# MCXA156 register map
Vendor: nxp.com; File version: 1.0
CPU: CM33 r2p0, little endian, no MPU, FPU, VTOR, 3 interrupt priority bits
Registers are 32-bit, read-write, reset 0x0 unless marked. A register's access mark holds for its fields unless they carry their own. Offsets are from the block's base; [hi:lo] are bit positions; {n}, {i} and the like mark numbered series.

## FLEXIO0 — FLEXIO
Base 0x40099000
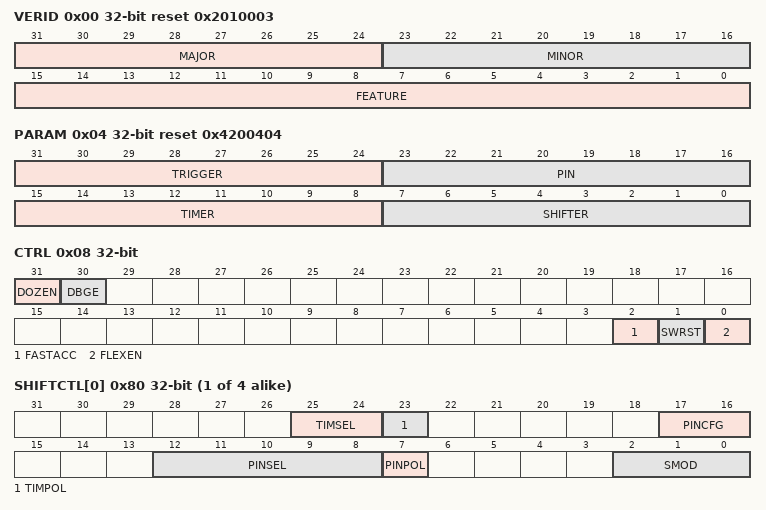
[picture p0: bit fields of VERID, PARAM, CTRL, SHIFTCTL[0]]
0x00 VERID ro reset 0x2010003 — Version ID
  [31:24] MAJOR — Major Version Number
  [23:16] MINOR — Minor Version Number
  [15:0] FEATURE — Feature Specification Number
    0=Standard features implemented; 1=state_logic_parallel (State, logic, and parallel modes supported); 2=pinctrl (Pin control registers supported); 3=state_logic_parallel_pinctrl (State, logic, and parallel modes, plus pin control registers supported)
0x04 PARAM ro reset 0x4200404 — Parameter
  [31:24] TRIGGER — Trigger Number
  [23:16] PIN — Pin Number
  [15:8] TIMER — Timer Number
  [7:0] SHIFTER — Shifter Number
0x08 CTRL — FLEXIO Control
  [31] DOZEN — Doze Enable
    0=enable; 1=disable
  [30] DBGE — Debug Enable
    0=disable; 1=emable (Enable)
  [2] FASTACC — Fast Access
    0=normal; 1=fast
  [1] SWRST — Software Reset
    0=Disabled; 1=Enabled
  [0] FLEXEN — FLEXIO Enable
    0=disable; 1=enable
0x0C PIN ro — Pin State
  [31:0] PDI — Pin Data Input
0x10 SHIFTSTAT write-1-clears — Shifter Status
  [3:0] SSF write-1-clears — Shifter Status Flag
    on read: 0=CLR (Clear); 1=SET
0x14 SHIFTERR write-1-clears — Shifter Error
  [3:0] SEF write-1-clears — Shifter Error Flag
    on read: 0=CLR (Clear); 1=SET
0x18 TIMSTAT write-1-clears — Timer Status Flag
  [3:0] TSF write-1-clears
    on read: 0=CLR (Clear); 1=SET
0x20 SHIFTSIEN — Shifter Status Interrupt Enable
  [3:0] SSIE
0x24 SHIFTEIEN — Shifter Error Interrupt Enable
  [3:0] SEIE
0x28 TIMIEN — Timer Interrupt Enable
  [3:0] TEIE — Timer Status Interrupt Enable
0x30 SHIFTSDEN — Shifter Status DMA Enable
  [3:0] SSDE
0x38 TIMERSDEN — Timer Status DMA Enable
  [3:0] TSDE
0x40 SHIFTSTATE — Shifter State
  [2:0] STATE — Current State Pointer
0x48 TRGSTAT write-1-clears — Trigger Status
  [3:0] ETSF write-1-clears — External Trigger Status Flag
    on read: 0=CLR (Clear); 1=SET
0x4C TRIGIEN — External Trigger Interrupt Enable
  [3:0] TRIE
0x50 PINSTAT write-1-clears — Pin Status
  [31:0] PSF write-1-clears — Pin Status Flag
    on read: 0=CLR (Clear); 1=SET
0x54 PINIEN — Pin Interrupt Enable
  [31:0] PSIE — Pin Status Interrupt Enable
0x58 PINREN — Pin Rising Edge Enable
  [31:0] PRE — Pin Rising Edge
0x5C PINFEN — Pin Falling Edge Enable
  [31:0] PFE — Pin Falling Edge
0x60 PINOUTD — Pin Output Data
  [31:0] OUTD — Output Data
0x64 PINOUTE — Pin Output Enable
  [31:0] OUTE — Output Enable
0x68 PINOUTDIS — Pin Output Disable
  [31:0] OUTDIS — Output Disable
0x6C PINOUTCLR — Pin Output Clear
  [31:0] OUTCLR — Output Clear
0x70 PINOUTSET — Pin Output Set
  [31:0] OUTSET — Output Set
0x74 PINOUTTOG — Pin Output Toggle
  [31:0] OUTTOG — Output Toggle
{0x80+4i} SHIFTCTL[{i}] (i=0..3) — Shifter Control
  [25:24] TIMSEL — Timer Select
  [23] TIMPOL — Timer Polarity
    0=posedge (Positive edge); 1=negedge (Negative edge)
  [17:16] PINCFG — Shifter Pin Configuration
    0=disable (Shifter pin output disabled); 1=opend_bidirouten (Shifter pin open-drain or bidirectional output enable); 2=bidir_outdata (Shifter pin bidirectional output data); 3=output (Shifter pin output)
  [12:8] PINSEL — Shifter Pin Select
  [7] PINPOL — Shifter Pin Polarity
    0=active_high; 1=active_low
  [2:0] SMOD — Shifter Mode
    0=disable; 1=Receive mode; capture the current shifter content into SHIFTBUF on expiration of the timer; 2=Transmit mode; load SHIFTBUF contents into the shifter on expiration of the timer; 4=Match Store mode; shifter data is compared to SHIFTBUF content on expiration of the timer; 5=Match Continuous mode; shifter data is continuously compared to SHIFTBUF contents; 6=State mode; SHIFTBUF contents store programmable state attributes; 7=Logic mode; SHIFTBUF contents implement programmable logic lookup table
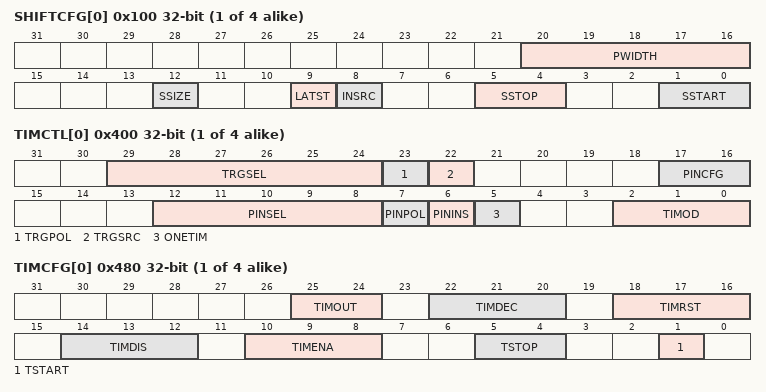
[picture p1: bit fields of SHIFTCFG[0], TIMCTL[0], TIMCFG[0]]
{0x100+4i} SHIFTCFG[{i}] (i=0..3) — Shifter Configuration
  [20:16] PWIDTH — Parallel Width
  [12] SSIZE — Shifter Size
    0=width32 (32-bit); 1=width24 (24-bit)
  [9] LATST — Late Store
    0=preshift (Store the pre-shift register state); 1=postshift (Store the post-shift register state)
  [8] INSRC — Input Source
    0=pin; 1=shifter_nplus1 (Shifter n+1 output)
  [5:4] SSTOP — Shifter Stop
    0=Stop bit disabled for Transmitter, Receiver, and Match Store modes; 1=Stop bit disabled for Transmitter, Receiver, and Match Store modes; when timer is in stop condition, Receiver and Match Store modes store receive data on the configured shift edge; 2=Transmitter mode outputs stop bit value 0 in Match Store mode; if stop bit is not 0, Receiver and Match Store modes set error flag (when timer is in stop condition, these modes also store receive data on the configured shift edge); 3=Transmitter mode outputs stop bit value 1 in Match Store mode; if stop bit is not 1, Receiver and Match Store modes set error flag (when timer is in stop condition, these modes also store receive data on the configured shift edge)
  [1:0] SSTART — Shifter Start
    0=Start bit disabled for Transmitter, Receiver, and Match Store modes; Transmitter mode loads data on enable; 1=Start bit disabled for Transmitter, Receiver, and Match Store modes; Transmitter mode loads data on first shift; 2=Transmitter mode outputs start bit value 0 before loading data on first shift; if start bit is not 0, Receiver and Match Store modes set error flag; 3=Transmitter mode outputs start bit value 1 before loading data on first shift; if start bit is not 1, Receiver and Match Store modes set error flag
{0x200+4i} SHIFTBUF[{i}] (i=0..3) — Shifter Buffer
  [31:0] SHIFTBUF — Shift Buffer
{0x280+4i} SHIFTBUFBIS[{i}] (i=0..3) — Shifter Buffer Bit Swapped
  [31:0] SHIFTBUFBIS — Shift Buffer
{0x300+4i} SHIFTBUFBYS[{i}] (i=0..3) — Shifter Buffer Byte Swapped
  [31:0] SHIFTBUFBYS — Shift Buffer
{0x380+4i} SHIFTBUFBBS[{i}] (i=0..3) — Shifter Buffer Bit Byte Swapped
  [31:0] SHIFTBUFBBS — Shift Buffer
{0x400+4i} TIMCTL[{i}] (i=0..3) — Timer Control
  [29:24] TRGSEL — Trigger Select
  [23] TRGPOL — Trigger Polarity
    0=active_high; 1=active_low
  [22] TRGSRC — Trigger Source
    0=ext_trig (External); 1=internal_trig
  [17:16] PINCFG — Timer Pin Configuration
    0=outdisable (Timer pin output disabled); 1=opend_bidirouten (Timer pin open-drain or bidirectional output enable); 2=bidir_outdata (Timer pin bidirectional output data); 3=output (Timer pin output)
  [12:8] PINSEL — Timer Pin Select
  [7] PINPOL — Timer Pin Polarity
    0=active_high; 1=active_low
  [6] PININS — Timer Pin Input Select
    0=PINSEL selects timer pin input and output; 1=pinselplus1 (PINSEL + 1 selects the timer pin input; timer pin output remains selected by PINSEL)
  [5] ONETIM — Timer One Time Operation
    0=not_blocked (Generate the timer enable event as normal); 1=blocked (Block the timer enable event unless the timer status flag is clear)
  [2:0] TIMOD — Timer Mode
    0=disable (Timer disabled); 1=dual8bit_baud (Dual 8-bit counters baud mode); 2=dual8bit_pwm_h (Dual 8-bit counters PWM high mode); 3=Single 16-bit counter mode; 4=single16bit_disable (Single 16-bit counter disable mode); 5=dual8bit_word (Dual 8-bit counters word mode); 6=dual8bit_pwm_l (Dual 8-bit counters PWM low mode); 7=single16bit_in_capture (Single 16-bit input capture mode)
{0x480+4i} TIMCFG[{i}] (i=0..3) — Timer Configuration
  [25:24] TIMOUT — Timer Output
    0=one (Logic one when enabled; not affected by timer reset); 1=zero (Logic zero when enabled; not affected by timer reset); 2=one_tmrreset (Logic one when enabled and on timer reset); 3=zero_tmrreset (Logic zero when enabled and on timer reset)
  [22:20] TIMDEC — Timer Decrement
    0=flexio_clk_shiftclk_tmr_out (Decrement counter on FLEXIO clock; shift clock equals timer output); 1=trig_edge_shiftclk_tmr_out (Decrement counter on trigger input (both edges); shift clock equals timer output); 2=pin_edge_shiftclk_tmr_out (Decrement counter on pin input (both edges); shift clock equals pin input); 3=trig_edge_shiftclk_trig_in (Decrement counter on trigger input (both edges); shift clock equals trigger input); 4=flexio_clk_div16_shiftclk_tmr_out (Decrement counter on FLEXIO clock divided by 16; shift clock equals timer output); 5=flexio_clk_div256_shiftclk_tmr_out (Decrement counter on FLEXIO clock divided by 256; shift clock equals timer output); 6=pin_rise_shiftclk_pin_in (Decrement counter on pin input (rising edge); shift clock equals pin input); 7=trig_rise_shiftclk_trig_in (Decrement counter on trigger input (rising edge); shift clock equals trigger input)
  [18:16] TIMRST — Timer Reset
    0=Never reset timer; 1=tmr_out_hi (Timer reset on timer output high.); 2=pin_eq_tmr_out (Timer reset on timer pin equal to timer output); 3=trig_eq_tmr_out (Timer reset on timer trigger equal to timer output); 4=pin_rise_edge (Timer reset on timer pin rising edge); 6=trig_rise_edge (Timer reset on trigger rising edge); 7=trig_edge (Timer reset on trigger rising or falling edge)
  [14:12] TIMDIS — Timer Disable
    0=never (Timer never disabled); 1=tmr_nminus1 (Timer disabled on timer n-1 disable); 2=tmr_cmp (Timer disabled on timer compare (upper 8 bits match and decrement)); 3=tmr_cmp_triglow (Timer disabled on timer compare (upper 8 bits match and decrement) and trigger low); 4=pin_edge (Timer disabled on pin rising or falling edge); 5=pin_edge_trighi (Timer disabled on pin rising or falling edge provided trigger is high); 6=trig_falledge (Timer disabled on trigger falling edge)
  [10:8] TIMENA — Timer Enable
    0=enable (Timer always enabled); 1=tmr_nminus1_en (Timer enabled on timer n-1 enable); 2=tmr_trighi_en (Timer enabled on trigger high); 3=tmr_trig_pin_hi_en (Timer enabled on trigger high and pin high); 4=tmr_pinrise_en (Timer enabled on pin rising edge); 5=tmr_pinrise_trighi_en (Timer enabled on pin rising edge and trigger high); 6=tmr_trigrise_en (Timer enabled on trigger rising edge); 7=tmr_trigedge_en (Timer enabled on trigger rising or falling edge)
  [5:4] TSTOP — Timer Stop
    0=stop_disable (Disabled); 1=enable_tmrcmp (Enabled on timer compare); 2=enable_tmrdisable (Enabled on timer disable); 3=enable_tmr_cmp_dis (Enabled on timer compare and timer disable)
  [1] TSTART — Timer Start
    0=Disabled; 1=Enabled
{0x500+4i} TIMCMP[{i}] (i=0..3) — Timer Compare
  [15:0] CMP — Timer Compare Value
{0x680+4i} SHIFTBUFNBS[{i}] (i=0..3) — Shifter Buffer Nibble Byte Swapped
  [31:0] SHIFTBUFNBS — Shift Buffer
{0x700+4i} SHIFTBUFHWS[{i}] (i=0..3) — Shifter Buffer Halfword Swapped
  [31:0] SHIFTBUFHWS — Shift Buffer
{0x780+4i} SHIFTBUFNIS[{i}] (i=0..3) — Shifter Buffer Nibble Swapped
  [31:0] SHIFTBUFNIS — Shift Buffer
{0x800+4i} SHIFTBUFOES[{i}] (i=0..3) — Shifter Buffer Odd Even Swapped
  [31:0] SHIFTBUFOES — Shift Buffer
{0x880+4i} SHIFTBUFEOS[{i}] (i=0..3) — Shifter Buffer Even Odd Swapped
  [31:0] SHIFTBUFEOS — Shift Buffer
{0x900+4i} SHIFTBUFHBS[{i}] (i=0..3) — Shifter Buffer Halfword Byte Swapped
  [31:0] SHIFTBUFHBS — Shift Buffer
